# cslr_rtc register map
Vendor: Texas Instruments
Peripheral module from a debugger description file (folder C5517).
Address unit: 16 bits
Registers are 16-bit, access not given, reset 0x0 unless marked. A register's access mark holds for its fields unless they carry their own. Offsets are as the file gives them; lines under a group give offsets from that group; [hi:lo] are bit positions; {n}, {i} and the like mark numbered series; 'fields as' and 'values as' point back to an identical list; <NAME> marks a mode.

## RTC — Real Time Clock
0x00 RTCINTEN — RTC Interrupt Enable
  [0] RTCINTEN rw — RTC interrupt enable
    0=DISABLED (RTC interrupt is disabled); 1=ENABLED (RTC interrupt is enabled)
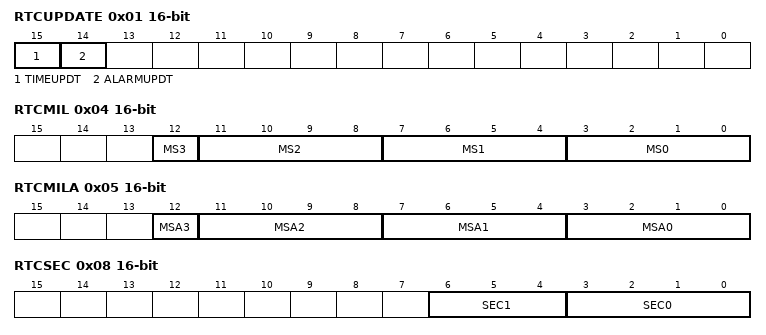
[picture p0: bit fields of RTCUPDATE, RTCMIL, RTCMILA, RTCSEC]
0x01 RTCUPDATE — Update RTC registers
  [15] TIMEUPDT rw — Initiates the Time updates
    0=CLEAR (RTC time comparison registers updated); 1=SET (Initiate update of the time registers)
  [14] ALARMUPDT rw — Initiates the alarm updates
    0=CLEAR (RTC alarm comparison registers updated); 1=SET (Initiate update of the Alamr Regiters)
0x04 RTCMIL — Milli Seconds Register
  [12] MS3 rw — Milli Seconds in BCD format digit 3
    0=zero (digit 3 of the MS BCD is 0); 1=one (digit 3 of the MS BCD is 1)
  [11:8] MS2 rw — Milli Seconds in BCD format digit 2
  [7:4] MS1 rw — milisecond in BCD fromat digit 1
  [3:0] MS0 rw — milisecond in BCD form at digit 0
0x05 RTCMILA — Milli Seconds Alarm Register
  [12] MSA3 rw — Triggers MS Alarm digit 3 (BCD)
    0=zero (digit 3 of the MS Alarm BCD is 0); 1=one (digit 3 of the MS Alarm BCD is 1)
  [11:8] MSA2 rw — Triggers MS Alarm digit 2 (BCD)
  [7:4] MSA1 rw — Triggers MS Alarm digit 1 (BCD)
  [3:0] MSA0 rw — Triggers MS Alarm digit 0 (BCD)
0x08 RTCSEC — Seconds Register
  [6:4] SEC1 rw — Seconds in BCD format digit 1
  [3:0] SEC0 rw — Seconds in BCD format digit 0
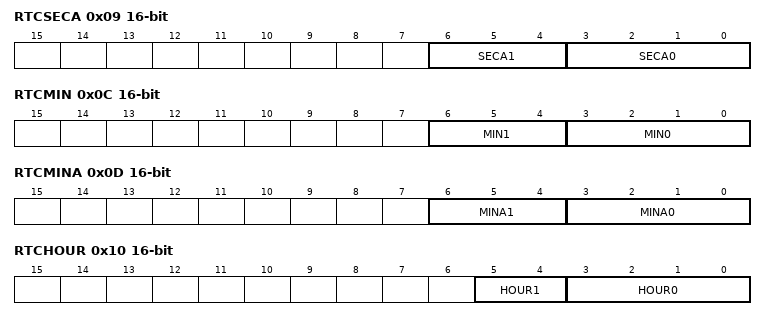
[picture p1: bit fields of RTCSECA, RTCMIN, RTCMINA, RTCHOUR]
0x09 RTCSECA — Seconds Alarm Register
  [6:4] SECA1 rw — Triggers Seconds Alarm in BCD format digit 1
  [3:0] SECA0 rw — Triggers Seconds Alarm in BCD format digit 0
0x0C RTCMIN — Minutes Register
  [6:4] MIN1 rw — Minutes in BCD format digit 1
  [3:0] MIN0 rw — Minutes in BCD format digit 0
0x0D RTCMINA — Minutes Alarm Register
  [6:4] MINA1 rw — Triggers Minutes Alarm in BCD format digit 1
  [3:0] MINA0 rw — Triggers Minutes Alarm in BCD format digit 0
0x10 RTCHOUR — Hours Register
  [5:4] HOUR1 rw — Hours in BCD format digit 1
  [3:0] HOUR0 rw — Hours in BCD format digit 0
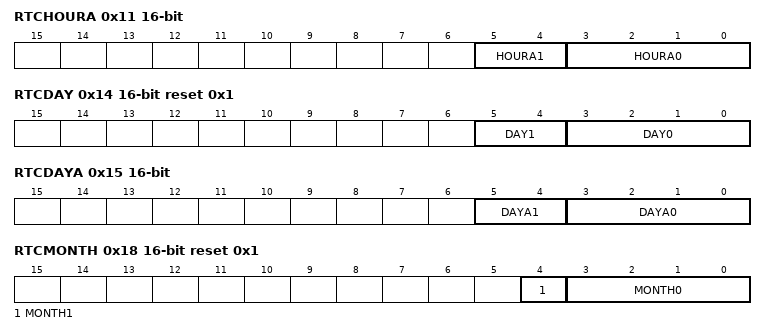
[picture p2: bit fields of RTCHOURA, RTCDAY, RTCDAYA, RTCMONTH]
0x11 RTCHOURA — Hours Alarm Register
  [5:4] HOURA1 rw — Triggers Hours Alarm (BCD format digit 1)
  [3:0] HOURA0 rw — Triggers Hours Alarm (BCD format digit 0)
0x14 RTCDAY reset 0x1 — Days Register
  [5:4] DAY1 rw — Day in BCD format digit 1
  [3:0] DAY0 rw — Day in BCD format digit 0
0x15 RTCDAYA — Days Alarm Register
  [5:4] DAYA1 rw — Triggers Day Alarm (BCD format digit 1)
  [3:0] DAYA0 rw — Triggers Day Alarm (BCD format digit 0)
0x18 RTCMONTH reset 0x1 — Months Register
  [4] MONTH1 rw — Month in BCD format digit 1
  [3:0] MONTH0 rw — Month in BCD format digit 0
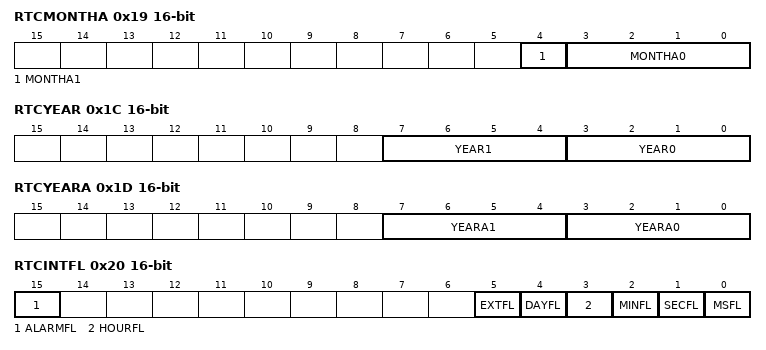
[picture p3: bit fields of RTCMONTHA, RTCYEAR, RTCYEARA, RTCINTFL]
0x19 RTCMONTHA — Months Alarm Register
  [4] MONTHA1 rw — Triggers Month Alarm (BCD format digit 1)
  [3:0] MONTHA0 rw — Triggers Month Alarm (BCD format digit 0)
0x1C RTCYEAR — Year Register
  [7:4] YEAR1 rw — Year in BCD format digit 1 (20XX)
  [3:0] YEAR0 rw — Year in BCD format digit 0 (20XX)
0x1D RTCYEARA — Years Alarm Register
  [7:4] YEARA1 rw — Triggers Year Alarm (BCD format digit 1 (20XX))
  [3:0] YEARA0 rw — Triggers Year Alarm (BCD format digit 0 (20XX))
0x20 RTCINTFL — RTC Status Register
  [15] ALARMFL rw — Indicates that an alarm interrupt has been generated
    0=CLEAR (Alarm interrupt did not occur); 1=SET (Alarm interrupt occurred (write 1 to clear))
  [5] EXTFL rw — Ext event has occurred
    0=CLEAR (External event interrupt has not occurred); 1=SET (external event interrupt occurred (write 1 to clear))
  [4] DAYFL rw — Day event has occurred
    0=CLEAR (Periodic day event has not occurred); 1=SET (Periodic Day event occurred (write 1 to clear))
  [3] HOURFL rw — hour event has occurred
    0=CLEAR (Periodic Hour event has not occurred); 1=SET (Periodic Hour event occurred (write 1 to clear))
  [2] MINFL rw — Minute Event has occurred
    0=CLEAR (Periodic Minute event has not occurred); 1=SET (Periodic Minute event occurred (write 1 to clear))
  [1] SECFL rw — Second Event occurred
    0=CLEAR (Periodic Second event has not occurred); 1=SET (Periodic Second event occurred (write 1 to clear))
  [0] MSFL rw — Milli second event occurred
    0=CLEAR (Periodic Milisecond event has not occurred); 1=SET (Periodic Milisecond event occurred (write 1 to clear))
0x21 RTCNOPWR reset 0x1 — Power lost status bit
  [0] PWRUP ro — RTC has lost power Flag
    0=clear (RTC has not lost power since software reset); 1=set (RTC has lost power and requires a software reset)
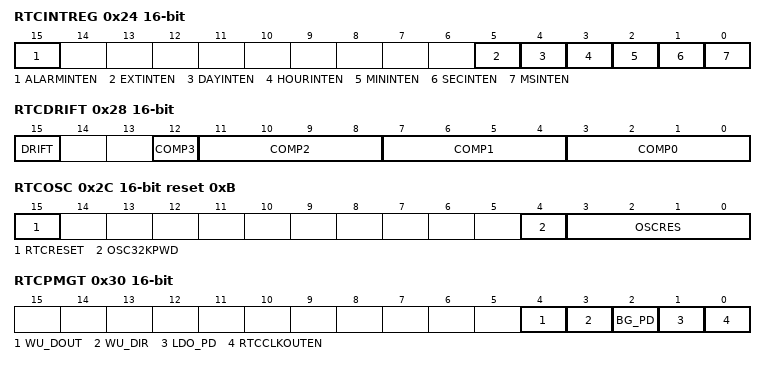
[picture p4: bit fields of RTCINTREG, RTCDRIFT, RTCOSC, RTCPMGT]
0x24 RTCINTREG — RTC Interrupt Register
  [15] ALARMINTEN rw — Alarm interrupt enable
    values as RTCINTFL.ALARMFL
  [5] EXTINTEN rw — Ext event interrupt enable
    0=CLEAR (External event interrupt not enabled); 1=SET (external event interrupt enabled)
  [4] DAYINTEN rw — Day event interrupt enable
    0=CLEAR (Periodic day event not enabled); 1=SET (Periodic Day event enabled)
  [3] HOURINTEN rw — hour event interrupt enable
    0=CLEAR (Periodic Hour event not enabled); 1=SET (Periodic Hour event enabled)
  [2] MININTEN rw — Minute Event interrupt enable
    0=CLEAR (Periodic Minute event not enabled); 1=SET (Periodic Minute event enabled)
  [1] SECINTEN rw — Second Event interrupt enable
    0=CLEAR (Periodic Second event not enabled); 1=SET (Periodic Second event enabled)
  [0] MSINTEN rw — Milli second event interrupt enable
    0=CLEAR (Periodic Milisecond event not enabled); 1=SET (Periodic Milisecond event enabled)
0x28 RTCDRIFT — RTC Compensation Register in Milliseconds (BCD)
  [15] DRIFT rw — Positive or Negative Compensation
    0=NEG (Negative compensation); 1=POS (Positive compensation)
  [12] COMP3 rw — Digit 3 of compensation BCD
    0=zero (BCD digit is 0); 1=one (BCD digit is 1)
  [11:8] COMP2 rw — Digit 2 of compensation register (BCD)
  [7:4] COMP1 rw — Digit 1 of compensation register (BCD)
  [3:0] COMP0 rw — Digit 0 of compensation register (BCD)
0x2C RTCOSC reset 0xB — RTC Oscillator Register
  [15] RTCRESET rw — RTC software reset. The RTC only resets when this bit is set. The RTC is not reset when RESTN goes low. Once set, this bit is cleared by the RTC. Do not access any RTC register for three 32KHz clock cycles after setting this bit.
    0=clear (RTC not reset); 1=set (RTC reset)
  [4] OSC32KPWD rw — Control of 32khz Oscillator powerdown (Func. Mode)
    0=clear (RTC 32KHz oscillator enabled); 1=set (RTC 32KHz oscillator disabled. External crystal connected through 2 internal buffers.)
  [3:0] OSCRES rw — Value of the oscillator resistance
0x30 RTCPMGT — RTC Power Management Register
  [4] WU_DOUT rw — Wakeup output, activelow/Opnedrain
    0=Low (WAKEUP pin driven low); 1=High (WAKEUP pin is open drain output)
  [3] WU_DIR rw — Wakup pin control,High or opendrain
    0=In (WAKEUP pin is configured as and active high input); 1=Out (WAKEUP pin is configured as an open drain output)
  [2] BG_PD rw — Bandgap power down
    0=clear (Normal); 1=Set (request to powerdown Bandgap)
  [1] LDO_PD rw — LDO powerdown (Func. Mode)
    0=clear (Normal); 1=Set (request to powerdown LDO)
  [0] RTCCLKOUTEN rw — Clockout output enable
    0=disable (Clock output disabled); 1=enable (Clock output enabled)
0x60 RTCSCR1 rw — RTC LSW Scratch Register 1
  [15:0] SCRATCH0 — Scratch registers, available to program
0x61 RTCSCR2 rw — RTC MSW Scratch Register 2
  [15:0] SCRATCH2 — Scratch registers, available to program
0x64 RTCSCR3 rw — RTC LSW Scratch Register 3
  [15:0] SCRATCH3 — Scratch registers, available to program
0x65 RTCSCR4 rw — RTC MSW Scratch Register 4
  [15:0] SCRATCH4 — Scratch registers, available to program
0x6C RGKR_LSW rw — RTC Gate-Keeper Register LSW
  [15:0] GKC_LSW — Gate Keeper Code LSW. RTC register writes will be silently blocked unless a specific 32-bit value is written into this register first. RTC register reads are unaffected (will occur normally regardless of the value in this register). This register is updated by the 32 kHz clock, so the DSP must allow time after a write for the write to complete. The amount of time that writes are unblocked should be minimized to reduce the chances of RTC time corruption in the event of VDDC powerdown. 0x95A4_F1E0 = DSP writes to RTC registers are NOT blocked. others = DSP writes to RTC registers ARE blocked.
0x6D RGKR_MSW rw — RTC Gate-Keeper Register MSW
  [15:0] GKC_MSW — Gate Keeper Code MSW. RTC register writes will be silently blocked unless a specific 32-bit value is written into this register first. RTC register reads are unaffected (will occur normally regardless of the value in this register). This register is updated by the 32 kHz clock, so the DSP must allow time after a write for the write to complete. The amount of time that writes are unblocked should be minimized to reduce the chances of RTC time corruption in the event of VDDC powerdown. 0x95A4_F1E0 = DSP writes to RTC registers are NOT blocked. others = DSP writes to RTC registers ARE blocked.
